# CC2756 register map
File version: 1.0
CPU: CM4 r0p4, little endian, no MPU, no FPU, VTOR, 3 interrupt priority bits
Registers are 32-bit, read-write, reset 0x0 unless marked. A register's access mark holds for its fields unless they carry their own. Offsets are from the block's base; [hi:lo] are bit positions; {n}, {i} and the like mark numbered series; 'fields as' and 'values as' point back to an identical list.

## APU — The APU - Algorithm Processing Unit - is a generic mathematical acceleration module that is able to operate with single-precision floating point numbers (IEEE 754 format) and is optimized to work with complex numbers.
Base 0x400D2000
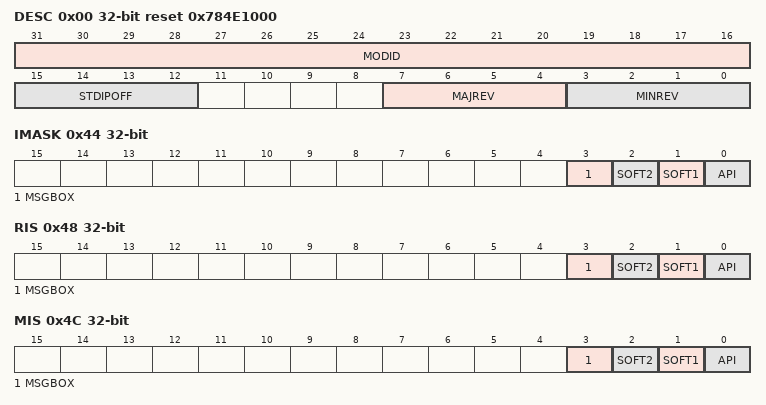
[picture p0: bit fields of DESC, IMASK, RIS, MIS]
0x00 DESC ro reset 0x784E1000 — IP Description
  [31:16] MODID — Module identifier
  [15:12] STDIPOFF — Standard IP MMR block offset
  [7:4] MAJREV — Major revision
  [3:0] MINREV — Minor revision
0x44 IMASK — Interrupt mask register
  [all] fields
    1=YES (The bit is 1); 0=ZERO (The bit is 0)
  [3] MSGBOX — Hardware defined interrupt triggered on msgbox write.
  [2] SOFT2 — Software defined interrupt. Not in use.
  [1] SOFT1 — Software defined interrupt. Not in use.
  [0] API — APU API finished mask.
0x48 RIS ro — Raw interrupt flag register
  [all] fields
    1=YES (The bit is 1); 0=ZERO (The bit is 0)
  [3] MSGBOX — Hardware defined interrupt triggered on msgbox write.
  [2] SOFT2 — Software defined interrupt. Not in use.
  [1] SOFT1 — Software defined interrupt. Not in use.
  [0] API — APU API finished. This flag is set when an API call is finished.
0x4C MIS ro — Masked interrupt flag register
  [all] fields
    1=YES (The bit is 1); 0=ZERO (The bit is 0)
  [3] MSGBOX — Hardware defined interrupt triggered on msgbox write.
  [2] SOFT2 — Software defined interrupt. Not in use.
  [1] SOFT1 — Software defined interrupt. Not in use.
  [0] API — APU API finished masked interrupt status.
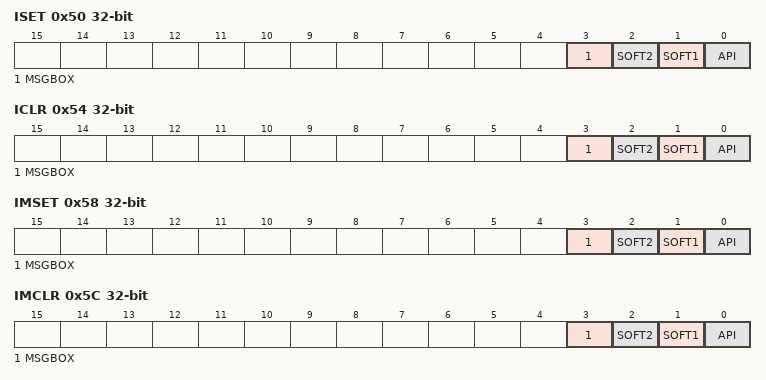
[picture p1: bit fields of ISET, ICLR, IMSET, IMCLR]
0x50 ISET wo — Interrupt flag set register
  [all] fields
    1=YES (The bit is 1); 0=ZERO (The bit is 0)
  [3] MSGBOX — Hardware defined interrupt triggered on msgbox write.
  [2] SOFT2 — Software defined interrupt. Not in use.
  [1] SOFT1 — Software defined interrupt. Not in use.
  [0] API — Set the APU API finish interrupt.
0x54 ICLR wo — Interrupt flag clear register
  [all] fields
    1=YES (The bit is 1); 0=ZERO (The bit is 0)
  [3] MSGBOX — Hardware defined interrupt triggered on msgbox write.
  [2] SOFT2 — Software defined interrupt. Not in use.
  [1] SOFT1 — Software defined interrupt. Not in use.
  [0] API — Clear the APU API finish interrupt.
0x58 IMSET wo — Interrupt mask set register
  [all] fields
    1=YES (The bit is 1); 0=ZERO (The bit is 0)
  [3] MSGBOX — Hardware defined interrupt triggered on msgbox write.
  [2] SOFT2 — Software defined interrupt. Not in use.
  [1] SOFT1 — Software defined interrupt. Not in use.
  [0] API — Set the APU API finish mask.
0x5C IMCLR wo — Interrupt mask clear register
  [all] fields
    1=YES (The bit is 1); 0=ZERO (The bit is 0)
  [3] MSGBOX — Hardware defined interrupt triggered on msgbox write.
  [2] SOFT2 — Software defined interrupt. Not in use.
  [1] SOFT1 — Software defined interrupt. Not in use.
  [0] API — Clear the APU API finish mask.
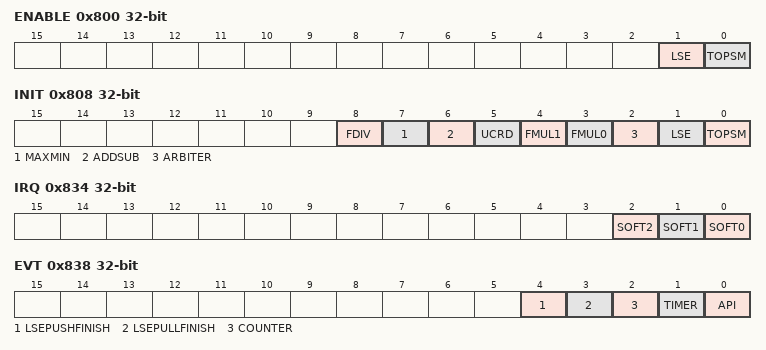
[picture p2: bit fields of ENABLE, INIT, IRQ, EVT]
0x800 ENABLE — Internal. Only to be used through TI provided API.
  [1] LSE — Internal. Only to be used through TI provided API.
    1=ONE (Internal. Only to be used through TI provided API.); 0=ZERO (Internal. Only to be used through TI provided API.)
  [0] TOPSM — Internal. Only to be used through TI provided API.
    values as LSE
0x804 FWSRC — Internal. Only to be used through TI provided API.
  [0] BANK
    values as ENABLE.LSE
0x808 INIT wo — Internal. Only to be used through TI provided API.
  [all] fields
    values as ENABLE.LSE
  [8] FDIV — Internal. Only to be used through TI provided API.
  [7] MAXMIN — Internal. Only to be used through TI provided API.
  [6] ADDSUB — Internal. Only to be used through TI provided API.
  [5] UCRD — Internal. Only to be used through TI provided API.
  [4] FMUL1 — Internal. Only to be used through TI provided API.
  [3] FMUL0 — Internal. Only to be used through TI provided API.
  [2] ARBITER — Internal. Only to be used through TI provided API.
  [1] LSE — Internal. Only to be used through TI provided API.
  [0] TOPSM — Internal. Only to be used through TI provided API.
0x80C PDREQ — Internal. Only to be used through TI provided API.
  [0] TOPSMPDREQ
    values as ENABLE.LSE
0x810 API — Internal. Only to be used through TI provided API.
  [4:0] CMD
    31=ALLONES (Internal. Only to be used through TI provided API.); 0=ALLZEROS (Internal. Only to be used through TI provided API.)
0x814 MSGBOX — Internal. Only to be used through TI provided API.
  [7:0] VAL
    255=ALLONES (Internal. Only to be used through TI provided API.); 0=ALLZEROS (Internal. Only to be used through TI provided API.)
0x818 CMDPAR0 — Internal. Only to be used through TI provided API.
  [10:0] VAL
    values as MSGBOX.VAL
{0x818+4i} CMDPAR{i} (i=1..5) — Internal. Only to be used through TI provided API.
  [10:0] VAL
0x830 STROBES wo — Internal. Only to be used through TI provided API.
  [0] S0
    values as ENABLE.LSE
0x834 IRQ wo — Internal. Only to be used through TI provided API.
  [all] fields
    1=YES (Internal. Only to be used through TI provided API.); 0=ZERO (Internal. Only to be used through TI provided API.)
  [2] SOFT2 — Internal. Only to be used through TI provided API.
  [1] SOFT1 — Internal. Only to be used through TI provided API.
  [0] SOFT0 — Internal. Only to be used through TI provided API.
0x838 EVT ro — Internal. Only to be used through TI provided API.
  [all] fields
    values as ENABLE.LSE
  [4] LSEPUSHFINISH — Internal. Only to be used through TI provided API.
  [3] LSEPULLFINISH — Internal. Only to be used through TI provided API.
  [2] COUNTER — Internal. Only to be used through TI provided API.
  [1] TIMER — Internal. Only to be used through TI provided API.
  [0] API — Internal. Only to be used through TI provided API.
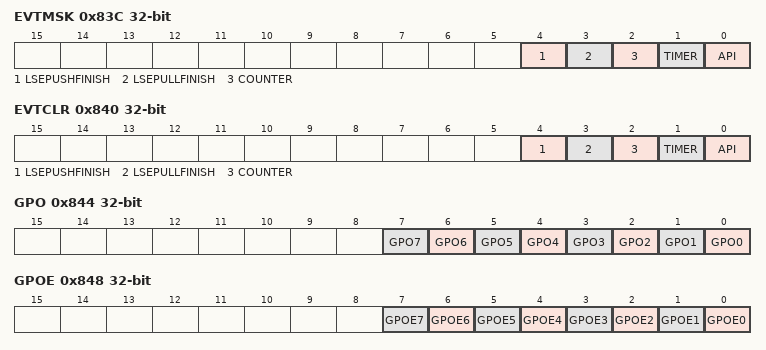
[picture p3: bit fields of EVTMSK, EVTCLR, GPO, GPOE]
0x83C EVTMSK — Internal. Only to be used through TI provided API.
  fields as EVT
0x840 EVTCLR wo — Internal. Only to be used through TI provided API.
  fields as EVT
0x844 GPO — Internal. Only to be used through TI provided API.
  [all] fields
    values as ENABLE.LSE
  [n] GPO{n} (n=0..7) — Internal. Only to be used through TI provided API.
0x848 GPOE — Internal. Only to be used through TI provided API.
  [all] fields
    values as ENABLE.LSE
  [n] GPOE{n} (n=0..7) — Internal. Only to be used through TI provided API.
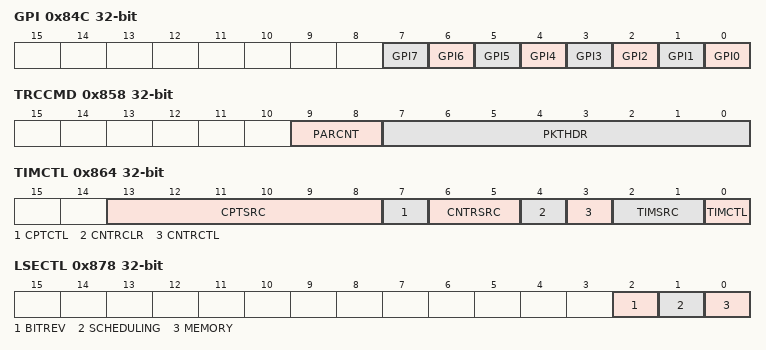
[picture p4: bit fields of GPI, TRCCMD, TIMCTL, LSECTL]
0x84C GPI ro — Internal. Only to be used through TI provided API.
  [all] fields
    values as ENABLE.LSE
  [n] GPI{n} (n=0..7) — Internal. Only to be used through TI provided API.
0x850 TRCCTL wo — Internal. Only to be used through TI provided API.
  [0] SEND
    values as ENABLE.LSE
0x854 TRCSTAT ro — Internal. Only to be used through TI provided API.
  [0] BUSY
    values as ENABLE.LSE
0x858 TRCCMD — Internal. Only to be used through TI provided API.
  [9:8] PARCNT — Internal. Only to be used through TI provided API.
    3=ALLONES (Internal. Only to be used through TI provided API.); 0=ALLZEROS (Internal. Only to be used through TI provided API.)
  [7:0] PKTHDR — Internal. Only to be used through TI provided API.
    values as MSGBOX.VAL
0x85C TRCPAR0 — Internal. Only to be used through TI provided API.
  [15:0] VAL
    0xFFFF=ALLONES (Internal. Only to be used through TI provided API.); 0=ALLZEROS (Internal. Only to be used through TI provided API.)
0x860 TRCPAR1 — Internal. Only to be used through TI provided API.
  fields as TRCPAR0
0x864 TIMCTL — Internal. Only to be used through TI provided API.
  [13:8] CPTSRC — Internal. Only to be used through TI provided API.
  [7] CPTCTL — Internal. Only to be used through TI provided API.
    1=ENABLE (Internal. Only to be used through TI provided API.); 0=DISABLE (Internal. Only to be used through TI provided API.)
  [6:5] CNTRSRC — Internal. Only to be used through TI provided API.
    0=CLK (Internal. Only to be used through TI provided API.)
  [4] CNTRCLR — Internal. Only to be used through TI provided API.
    values as ENABLE.LSE
  [3] CNTRCTL — Internal. Only to be used through TI provided API.
    values as ENABLE.LSE
  [2:1] TIMSRC — Internal. Only to be used through TI provided API.
    0=CLK (Internal. Only to be used through TI provided API.)
  [0] TIMCTL — Internal. Only to be used through TI provided API.
    values as CPTCTL
0x868 TIMINC — Internal. Only to be used through TI provided API.
  fields as TRCPAR0
0x86C TIMPER — Internal. Only to be used through TI provided API.
  [15:0] VAL
0x870 TIMCNT ro — Internal. Only to be used through TI provided API.
  [15:0] VAL
0x874 TIMCAPT ro — Internal. Only to be used through TI provided API.
  [15:0] VALUE
0x878 LSECTL — Internal. Only to be used through TI provided API.
  [2] BITREV — Internal. Only to be used through TI provided API.
    1=EN (Internal. Only to be used through TI provided API.); 0=DIS (Internal. Only to be used through TI provided API.)
  [1] SCHEDULING — Internal. Only to be used through TI provided API.
    1=HPIPELINE (Internal. Only to be used through TI provided API.); 0=PIPELINE (Internal. Only to be used through TI provided API.)
  [0] MEMORY — Internal. Only to be used through TI provided API.
    1=INTERLEAVED (Internal. Only to be used through TI provided API.); 0=MIRRORED (Internal. Only to be used through TI provided API.)
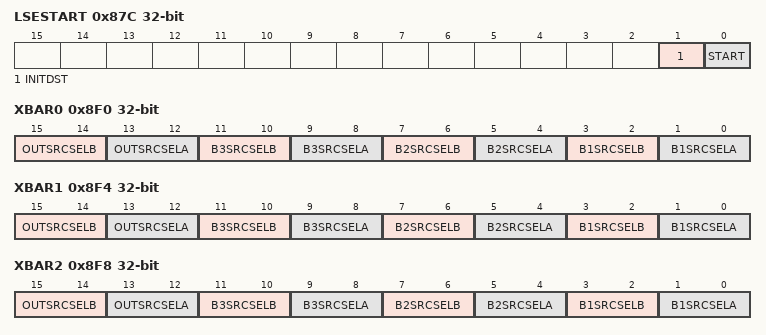
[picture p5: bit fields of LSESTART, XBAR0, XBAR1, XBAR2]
0x87C LSESTART wo — Internal. Only to be used through TI provided API.
  [1] INITDST — Internal. Only to be used through TI provided API.
  [0] START — Internal. Only to be used through TI provided API.
0x880 LSEBASESRCA — Internal. Only to be used through TI provided API.
  [10:0] VAL
0x884 LSEMODESRCA — Internal. Only to be used through TI provided API.
  [3:0] VAL
    10=UNITCIRC (Internal. Only to be used through TI provided API.); 9=CONJVEC (Internal. Only to be used through TI provided API.); 8=PUSHC (Internal. Only to be used through TI provided API.); 7=LOADK (Internal. Only to be used through TI provided API.); 6=IFFT (Internal. Only to be used through TI provided API.); 5=FFT (Internal. Only to be used through TI provided API.); 4=DIAG (Internal. Only to be used through TI provided API.); 3=SYM (Internal. Only to be used through TI provided API.); 2=HERM (Internal. Only to be used through TI provided API.); 1=MATRIX (Internal. Only to be used through TI provided API.); 0=VECTOR (Internal. Only to be used through TI provided API.)
0x888 LSESUBMODESRCA — Internal. Only to be used through TI provided API.
  [0] VAL
    1=COL (Internal. Only to be used through TI provided API.); 0=ROW (Internal. Only to be used through TI provided API.)
0x88C LSENSRCA — Internal. Only to be used through TI provided API.
  [10:0] VAL
0x890 LSEMSRCA — Internal. Only to be used through TI provided API.
  [10:0] VAL
0x894 LSEELEMENTSRCA — Internal. Only to be used through TI provided API.
  [10:0] VAL
0x898 LSESTRIDESRCA — Internal. Only to be used through TI provided API.
  [1:0] VAL
0x89C LSEBASEDSTA — Internal. Only to be used through TI provided API.
  [10:0] VAL
0x8A0 LSEMODEDSTA — Internal. Only to be used through TI provided API.
  [3:0] VAL
    9=CONJVEC (Internal. Only to be used through TI provided API.); 8=PUSHC (Internal. Only to be used through TI provided API.); 7=LOADK (Internal. Only to be used through TI provided API.); 6=IFFT (Internal. Only to be used through TI provided API.); 5=FFT (Internal. Only to be used through TI provided API.); 4=DIAG (Internal. Only to be used through TI provided API.); 3=SYM (Internal. Only to be used through TI provided API.); 2=HERM (Internal. Only to be used through TI provided API.); 1=MATRIX (Internal. Only to be used through TI provided API.); 0=VECTOR (Internal. Only to be used through TI provided API.)
0x8A4 LSESUBMODEDSTA — Internal. Only to be used through TI provided API.
  fields as LSESUBMODESRCA
0x8A8 LSENDSTA — Internal. Only to be used through TI provided API.
  [10:0] VAL
0x8AC LSEMDSTA — Internal. Only to be used through TI provided API.
  [10:0] VAL
0x8B0 LSEELEMENTDSTA — Internal. Only to be used through TI provided API.
  [10:0] VAL
0x8B4 LSESTRIDEDSTA — Internal. Only to be used through TI provided API.
  [1:0] VAL
0x8B8 LSEBASESRCB — Internal. Only to be used through TI provided API.
  [10:0] VAL
0x8BC LSEMODESRCB — Internal. Only to be used through TI provided API.
  fields as LSEMODEDSTA
0x8C0 LSESUBMODESRCB — Internal. Only to be used through TI provided API.
  fields as LSESUBMODESRCA
0x8C4 LSENSRCB — Internal. Only to be used through TI provided API.
  [10:0] VAL
0x8C8 LSEMSRCB — Internal. Only to be used through TI provided API.
  [10:0] VAL
0x8CC LSEELEMENTSRCB — Internal. Only to be used through TI provided API.
  [10:0] VAL
0x8D0 LSESTRIDESRCB — Internal. Only to be used through TI provided API.
  [1:0] VAL
0x8D4 LSEBASEDSTB — Internal. Only to be used through TI provided API.
  [10:0] VAL
0x8D8 LSEMODEDSTB — Internal. Only to be used through TI provided API.
  fields as LSEMODEDSTA
0x8DC LSESUBMODEDSTB — Internal. Only to be used through TI provided API.
  fields as LSESUBMODESRCA
0x8E0 LSENDSTB — Internal. Only to be used through TI provided API.
  [10:0] VAL
0x8E4 LSEMDSTB — Internal. Only to be used through TI provided API.
  [10:0] VAL
0x8E8 LSEELEMENTDSTB — Internal. Only to be used through TI provided API.
  [10:0] VAL
0x8EC LSESTRIDEDSTB — Internal. Only to be used through TI provided API.
  [1:0] VAL
0x8F0 XBAR0 — Internal. Only to be used through TI provided API.
  [15:14] OUTSRCSELB — Internal. Only to be used through TI provided API.
    3=FMUL1 (Internal. Only to be used through TI provided API.); 2=FMUL0 (Internal. Only to be used through TI provided API.); 1=R2C (Internal. Only to be used through TI provided API.); 0=INPUT (Internal. Only to be used through TI provided API.)
  [13:12] OUTSRCSELA — Internal. Only to be used through TI provided API.
    values as OUTSRCSELB
  [11:10] B3SRCSELB — Internal. Only to be used through TI provided API.
    3=FMUL0 (Internal. Only to be used through TI provided API.); 2=R2C (Internal. Only to be used through TI provided API.); 1=INPUT (Internal. Only to be used through TI provided API.); 0=ZERO (Internal. Only to be used through TI provided API.)
  [9:8] B3SRCSELA — Internal. Only to be used through TI provided API.
    values as B3SRCSELB
  [7:6] B2SRCSELB — Internal. Only to be used through TI provided API.
    3=FMUL1 (Internal. Only to be used through TI provided API.); 2=R2C (Internal. Only to be used through TI provided API.); 1=INPUT (Internal. Only to be used through TI provided API.); 0=ZERO (Internal. Only to be used through TI provided API.)
  [5:4] B2SRCSELA — Internal. Only to be used through TI provided API.
    values as B2SRCSELB
  [3:2] B1SRCSELB — Internal. Only to be used through TI provided API.
    3=FMUL1 (Internal. Only to be used through TI provided API.); 2=FMUL0 (Internal. Only to be used through TI provided API.); 1=INPUT (Internal. Only to be used through TI provided API.); 0=ZERO (Internal. Only to be used through TI provided API.)
  [1:0] B1SRCSELA — Internal. Only to be used through TI provided API.
    values as B1SRCSELB
0x8F4 XBAR1 — Internal. Only to be used through TI provided API.
  [15:14] OUTSRCSELB — Internal. Only to be used through TI provided API.
    3=ADDSUB (Internal. Only to be used through TI provided API.); 2=UCRD (Internal. Only to be used through TI provided API.); 1=SINCOS (Internal. Only to be used through TI provided API.); 0=INPUT (Internal. Only to be used through TI provided API.)
  [13:12] OUTSRCSELA — Internal. Only to be used through TI provided API.
    values as OUTSRCSELB
  [11:10] B3SRCSELB — Internal. Only to be used through TI provided API.
    3=UCRD (Internal. Only to be used through TI provided API.); 2=SINCOS (Internal. Only to be used through TI provided API.); 1=INPUT (Internal. Only to be used through TI provided API.); 0=ZERO (Internal. Only to be used through TI provided API.)
  [9:8] B3SRCSELA — Internal. Only to be used through TI provided API.
    values as B3SRCSELB
  [7:6] B2SRCSELB — Internal. Only to be used through TI provided API.
    3=ADDSUB (Internal. Only to be used through TI provided API.); 2=SINCOS (Internal. Only to be used through TI provided API.); 1=INPUT (Internal. Only to be used through TI provided API.); 0=ZERO (Internal. Only to be used through TI provided API.)
  [5:4] B2SRCSELA — Internal. Only to be used through TI provided API.
    values as B2SRCSELB
  [3:2] B1SRCSELB — Internal. Only to be used through TI provided API.
    3=ADDSUB (Internal. Only to be used through TI provided API.); 2=UCRD (Internal. Only to be used through TI provided API.); 1=INPUT (Internal. Only to be used through TI provided API.); 0=ZERO (Internal. Only to be used through TI provided API.)
  [1:0] B1SRCSELA — Internal. Only to be used through TI provided API.
    values as B1SRCSELB
0x8F8 XBAR2 — Internal. Only to be used through TI provided API.
  [15:14] OUTSRCSELB — Internal. Only to be used through TI provided API.
    3=FDIV (Internal. Only to be used through TI provided API.); 2=FX2FP (Internal. Only to be used through TI provided API.); 1=MAXMIN (Internal. Only to be used through TI provided API.); 0=INPUT (Internal. Only to be used through TI provided API.)
  [13:12] OUTSRCSELA — Internal. Only to be used through TI provided API.
    values as OUTSRCSELB
  [11:10] B3SRCSELB — Internal. Only to be used through TI provided API.
    3=FX2FP (Internal. Only to be used through TI provided API.); 2=MAXMIN (Internal. Only to be used through TI provided API.); 1=INPUT (Internal. Only to be used through TI provided API.); 0=ZERO (Internal. Only to be used through TI provided API.)
  [9:8] B3SRCSELA — Internal. Only to be used through TI provided API.
    values as B3SRCSELB
  [7:6] B2SRCSELB — Internal. Only to be used through TI provided API.
    3=FDIV (Internal. Only to be used through TI provided API.); 2=MAXMIN (Internal. Only to be used through TI provided API.); 1=INPUT (Internal. Only to be used through TI provided API.); 0=ZERO (Internal. Only to be used through TI provided API.)
  [5:4] B2SRCSELA — Internal. Only to be used through TI provided API.
    values as B2SRCSELB
  [3:2] B1SRCSELB — Internal. Only to be used through TI provided API.
    3=FDIV (Internal. Only to be used through TI provided API.); 2=FX2FP (Internal. Only to be used through TI provided API.); 1=INPUT (Internal. Only to be used through TI provided API.); 0=ZERO (Internal. Only to be used through TI provided API.)
  [1:0] B1SRCSELA — Internal. Only to be used through TI provided API.
    values as B1SRCSELB
0x8FC R2C — Internal. Only to be used through TI provided API.
  [2:0] OP
    6=ABS (Internal. Only to be used through TI provided API.); 5=IMA (Internal. Only to be used through TI provided API.); 4=RA (Internal. Only to be used through TI provided API.); 3=R2CCA (Internal. Only to be used through TI provided API.); 2=R2CA (Internal. Only to be used through TI provided API.); 1=R2CC (Internal. Only to be used through TI provided API.); 0=R2C (Internal. Only to be used through TI provided API.)
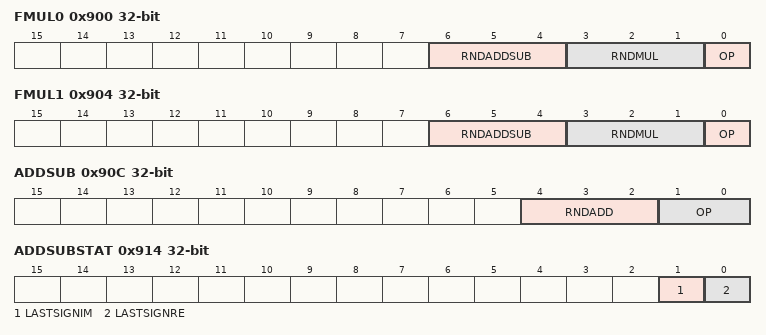
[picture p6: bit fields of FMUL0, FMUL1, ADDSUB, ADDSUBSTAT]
0x900 FMUL0 — Internal. Only to be used through TI provided API.
  [6:4] RNDADDSUB — Internal. Only to be used through TI provided API.
    5=AWAYZ (Internal. Only to be used through TI provided API.); 4=NEARU (Internal. Only to be used through TI provided API.); 3=NINF (Internal. Only to be used through TI provided API.); 2=PINF (Internal. Only to be used through TI provided API.); 1=ZERO (Internal. Only to be used through TI provided API.); 0=NEARE (Internal. Only to be used through TI provided API.)
  [3:1] RNDMUL — Internal. Only to be used through TI provided API.
    values as RNDADDSUB
  [0] OP — Internal. Only to be used through TI provided API.
    1=KMULT (Internal. Only to be used through TI provided API.); 0=MULT (Internal. Only to be used through TI provided API.)
0x904 FMUL1 — Internal. Only to be used through TI provided API.
  fields as FMUL0
0x908 UCRD — Internal. Only to be used through TI provided API.
  [0] MODE
    1=ROT (Internal. Only to be used through TI provided API.); 0=VECT (Internal. Only to be used through TI provided API.)
0x90C ADDSUB — Internal. Only to be used through TI provided API.
  [4:2] RNDADD — Internal. Only to be used through TI provided API.
    values as FMUL0.RNDADDSUB
  [1:0] OP — Internal. Only to be used through TI provided API.
    3=ACC (Internal. Only to be used through TI provided API.); 2=ADDK (Internal. Only to be used through TI provided API.); 1=SUB (Internal. Only to be used through TI provided API.); 0=ADD (Internal. Only to be used through TI provided API.)
0x910 ADDSUBDECACC — Internal. Only to be used through TI provided API.
  [9:0] VAL
0x914 ADDSUBSTAT — Internal. Only to be used through TI provided API.
  [1] LASTSIGNIM ro — Internal. Only to be used through TI provided API.
  [0] LASTSIGNRE ro — Internal. Only to be used through TI provided API.
0x918 MAXMIN — Internal. Only to be used through TI provided API.
  [0] OP
    1=MAX (Internal. Only to be used through TI provided API.); 0=MIN (Internal. Only to be used through TI provided API.)
0x91C MAXMINDECACC — Internal. Only to be used through TI provided API.
  [9:0] VAL
0x920 MAXMININDEX ro — Internal. Only to be used through TI provided API.
  [9:0] VAL
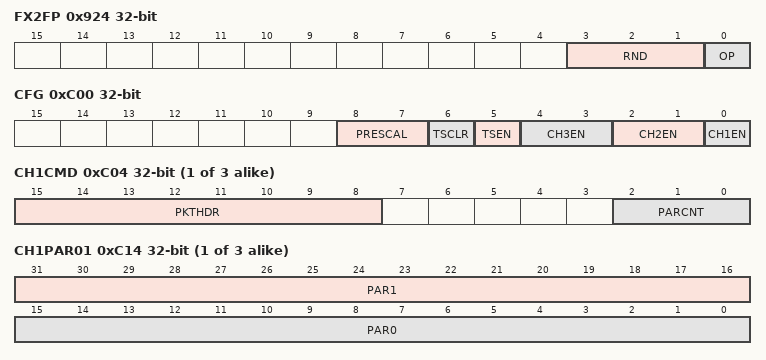
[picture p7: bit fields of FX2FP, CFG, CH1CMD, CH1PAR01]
0x924 FX2FP — Internal. Only to be used through TI provided API.
  [3:1] RND — Internal. Only to be used through TI provided API.
    6=NEARE (Internal. Only to be used through TI provided API.); 5=AWAYZ (Internal. Only to be used through TI provided API.); 4=NEARU (Internal. Only to be used through TI provided API.); 3=NINF (Internal. Only to be used through TI provided API.); 2=PINF (Internal. Only to be used through TI provided API.); 1=ZERO (Internal. Only to be used through TI provided API.)
  [0] OP — Internal. Only to be used through TI provided API.
    1=CONVR (Internal. Only to be used through TI provided API.); 0=CONVA (Internal. Only to be used through TI provided API.)
0x928 FX2FPR — Internal. Only to be used through TI provided API.
  [15:0] R
0x92C FX2FPCONVR wo — Internal. Only to be used through TI provided API.
  [0] INIT
    values as ENABLE.LSE
0x930 FDIV — Internal. Only to be used through TI provided API.
  [2:0] RND
    values as FX2FP.RND
0x934 FDIVSTAT ro — Internal. Only to be used through TI provided API.
  [0] DIVZERO
    1=SET (Internal. Only to be used through TI provided API.); 0=CLEAR (Internal. Only to be used through TI provided API.)
0xC00 CFG — Internal. Only to be used through TI provided API.
  [8:7] PRESCAL — Internal. Only to be used through TI provided API.
    {v}=DIV{v+1} (Internal. Only to be used through TI provided API.) (v=0..3)
  [6] TSCLR wo — Internal. Only to be used through TI provided API.
    values as ENABLE.LSE
  [5] TSEN — Internal. Only to be used through TI provided API.
    values as ENABLE.LSE
  [4:3] CH3EN — Internal. Only to be used through TI provided API.
    2=TOPSM (Internal. Only to be used through TI provided API.); 1=NORM (Internal. Only to be used through TI provided API.); 0=OFF (Internal. Only to be used through TI provided API.)
  [2:1] CH2EN — Internal. Only to be used through TI provided API.
    values as CH3EN
  [0] CH1EN — Internal. Only to be used through TI provided API.
    1=ENABLED (Internal. Only to be used through TI provided API.); 0=OFF (Internal. Only to be used through TI provided API.)
{0xC00+4i} CH{i}CMD (i=1..3) — Internal. Only to be used through TI provided API.
  [15:8] PKTHDR — Internal. Only to be used through TI provided API.
    values as MSGBOX.VAL
  [2:0] PARCNT — Internal. Only to be used through TI provided API.
    7=ALLONES (Internal. Only to be used through TI provided API.); 0=ALLZEROS (Internal. Only to be used through TI provided API.)
{0xC10+4i} CH{i}PAR01 (i=1..3) — Internal. Only to be used through TI provided API.
  [31:16] PAR1 — Internal. Only to be used through TI provided API.
    values as TRCPAR0.VAL
  [15:0] PAR0 — Internal. Only to be used through TI provided API.
    values as TRCPAR0.VAL
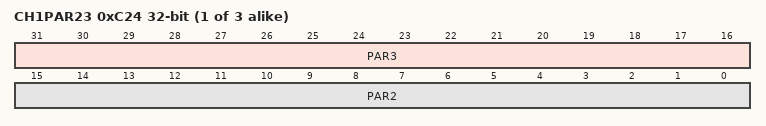
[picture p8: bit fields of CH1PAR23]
{0xC20+4i} CH{i}PAR23 (i=1..3) — Internal. Only to be used through TI provided API.
  [31:16] PAR3 — Internal. Only to be used through TI provided API.
    values as TRCPAR0.VAL
  [15:0] PAR2 — Internal. Only to be used through TI provided API.
    values as TRCPAR0.VAL
